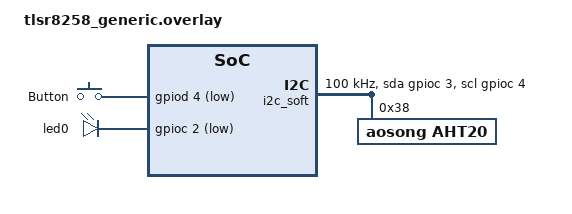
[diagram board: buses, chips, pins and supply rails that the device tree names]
/*
 * SPDX-License-Identifier: Apache-2.0
 *
 * HOBEIAN ZG-227Z: AHT20 on a software I2C, SDA PC3, SCL PC4.
 * The pin map is the one of the board in ts0201_tz3000_zed (src/common/board_*.h).
 * The battery is read on PC5 (VBAT mode, see sensor.dtsi).
 */

#include "../common/sensor.dtsi"

/ {
	aliases {
		sw0 = &button0;
		ambient-sensor = &aht20;
	};

	buttons {
		compatible = "gpio-keys";

		button0: button_0 {
			gpios = <&gpiod 4 (GPIO_ACTIVE_LOW | GPIO_PULL_UP)>;
			label = "Button";
		};
	};

	/* No hardware I2C on these pins: bit-banged, SDA PC3, SCL PC4 */
	i2c_soft: i2c {
		compatible = "gpio-i2c";
		clock-frequency = <I2C_BITRATE_STANDARD>;
		sda-gpios = <&gpioc 3 GPIO_PULL_UP>;
		scl-gpios = <&gpioc 4 GPIO_PULL_UP>;
		#address-cells = <1>;
		#size-cells = <0>;

		aht20: aht20@38 {
			compatible = "aosong,aht20";
			reg = <0x38>;
		};
	};
};

/* The status LED, off the board's default pin */
&led0 {
	gpios = <&gpioc 2 GPIO_ACTIVE_LOW>;
};
